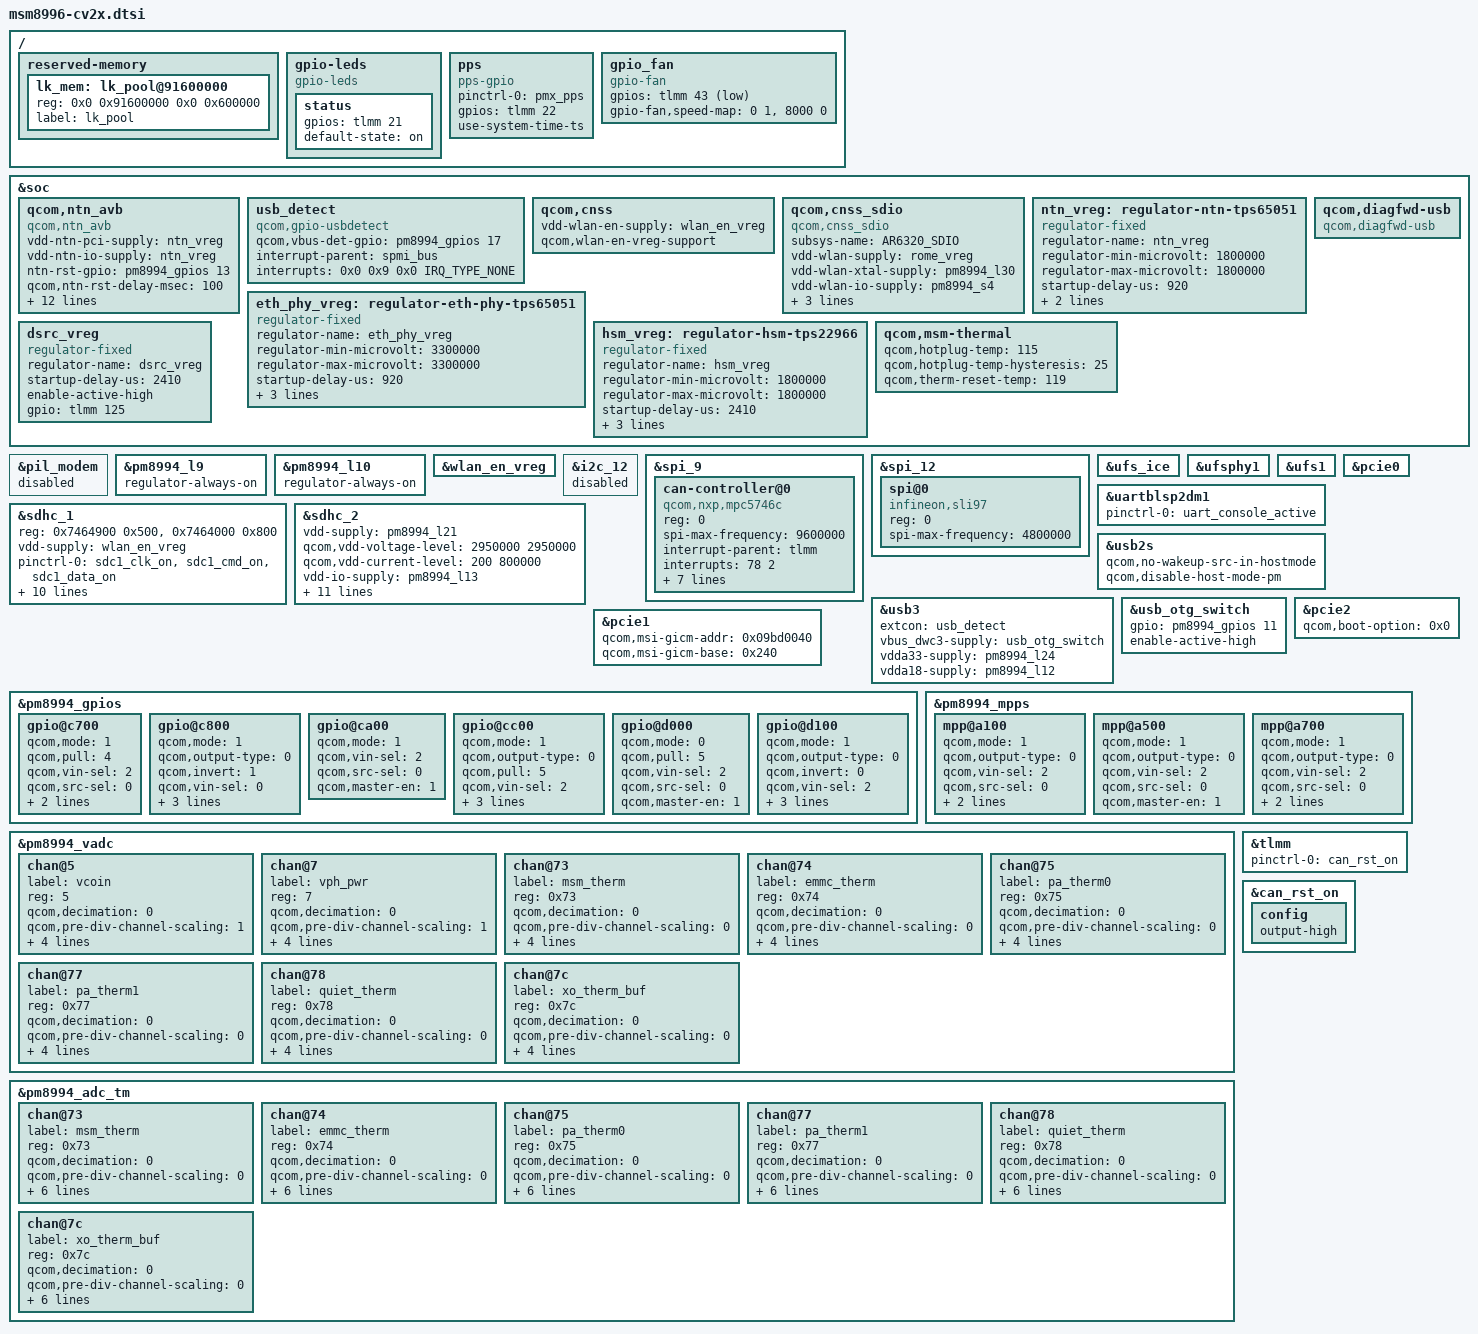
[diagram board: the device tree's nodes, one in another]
/* Copyright (c) 2017-2019, The Linux Foundation. All rights reserved.
 *
 * This program is free software; you can redistribute it and/or modify
 * it under the terms of the GNU General Public License version 2 and
 * only version 2 as published by the Free Software Foundation.
 *
 * This program is distributed in the hope that it will be useful,
 * but WITHOUT ANY WARRANTY; without even the implied warranty of
 * MERCHANTABILITY or FITNESS FOR A PARTICULAR PURPOSE.  See the
 * GNU General Public License for more details.
 */

#include "msm8996-pinctrl.dtsi"
#include "external-soc.dtsi"

/ {
	reserved-memory {
		lk_mem: lk_pool@91600000 {
			reg = <0x0 0x91600000 0x0 0x600000>;
			label = "lk_pool";
		};
	};

	gpio-leds {
		compatible = "gpio-leds";

		status {
			gpios = <&tlmm 21 0>;
			default-state = "on";
		};
	};

	pps {
		compatible = "pps-gpio";
		pinctrl-names = "default";
		pinctrl-0 = <&pmx_pps>;
		gpios = <&tlmm 22 0>;
		status = "okay";
		use-system-time-ts;
	};

	gpio_fan {
		/* Based on 5v 75mA MC30100V2 */
		compatible = "gpio-fan";
		gpios =  <&tlmm 43 GPIO_ACTIVE_LOW>;
		gpio-fan,speed-map = <0     1>,
				     <8000  0>;
	};
};

&soc {
	/delete-node/ sound-9335;

	qcom,ntn_avb {
		compatible = "qcom,ntn_avb";
		vdd-ntn-pci-supply = <&ntn_vreg>;
		vdd-ntn-io-supply = <&ntn_vreg>;
		ntn-rst-gpio = <&pm8994_gpios 13 0>;
		qcom,ntn-rst-delay-msec = <100>;
		qcom,ntn-rc-num = <1>;
		qcom,ntn-bus-num = <1>;
		qcom,ntn-mdio-bus-id = <1>;
		qcom,ntn-phy-addr = <7>;
		qcom,msm-bus,name = "ntn";
		qcom,msm-bus,num-cases = <2>;
		qcom,msm-bus,num-paths = <1>;
		qcom,msm-bus,vectors-KBps =
				<100 512 0 0>,
				<100 512 207108 14432000>;
		qcom,ntn-pcierst-resx;
		qcom,txc-skew-ps = <1860>;
		qcom,rxc-skew-ps = <1860>;
	};

	usb_detect: usb_detect {
		compatible = "qcom,gpio-usbdetect";
		qcom,vbus-det-gpio = <&pm8994_gpios 17 0>;
		interrupt-parent = <&spmi_bus>;
		interrupts = <0x0 0x9 0x0 IRQ_TYPE_NONE>;
		interrupt-names ="pmic_id_irq";
	};

	qcom,cnss {
		vdd-wlan-en-supply = <&wlan_en_vreg>;
		qcom,wlan-en-vreg-support;
		/delete-property/ wlan-en-gpio;
		/delete-property/ wlan-bootstrap-gpio;
		/delete-property/ vdd-wlan-core-supply;
	};

	qcom,cnss_sdio {
		compatible = "qcom,cnss_sdio";
		subsys-name = "AR6320_SDIO";
		vdd-wlan-supply = <&rome_vreg>;
		vdd-wlan-xtal-supply = <&pm8994_l30>;
		vdd-wlan-io-supply = <&pm8994_s4>;
		vdd-wlan-dsrc-supply = <&dsrc_vreg>;
		qcom,wlan-ramdump-dynamic = <0x200000>;
		qcom,skip-wlan-en-toggle;
	};

	ntn_vreg: regulator-ntn-tps65051 {
		compatible = "regulator-fixed";
		regulator-name = "ntn_vreg";
		regulator-min-microvolt = <1800000>;
		regulator-max-microvolt = <1800000>;
		startup-delay-us = <920>;
		gpio = <&tlmm 138 0>;
		enable-active-high;
	};

	eth_phy_vreg: regulator-eth-phy-tps65051 {
		compatible = "regulator-fixed";
		regulator-name = "eth_phy_vreg";
		regulator-min-microvolt = <3300000>;
		regulator-max-microvolt = <3300000>;
		startup-delay-us = <920>;
		gpio = <&tlmm 136 0>;
		enable-active-high;
		regulator-always-on;
	};

	hsm_vreg: regulator-hsm-tps22966 {
		compatible = "regulator-fixed";
		regulator-name = "hsm_vreg";
		regulator-min-microvolt = <1800000>;
		regulator-max-microvolt = <1800000>;
		startup-delay-us = <2410>;
		gpio = <&tlmm 81 0>;
		enable-active-high;
		regulator-always-on;
	};

	dsrc_vreg: dsrc_vreg {
		compatible = "regulator-fixed";
		regulator-name = "dsrc_vreg";
		startup-delay-us = <2410>;
		enable-active-high;
		gpio = <&tlmm 125 0>;
	};

	qcom,diagfwd-usb {
		compatible = "qcom,diagfwd-usb";
		status = "okay";
	};
};

/delete-node/ &mdss_mdp;
/delete-node/ &mdss_dsi;
/delete-node/ &msm_ext_disp;
/delete-node/ &msm_wb_disp;
/delete-node/ &mdss_hdmi_tx;
/delete-node/ &mdss_rotator;
/delete-node/ &routing;

&pil_modem {
	status = "disabled";
};

&pm8994_l9 {
	regulator-always-on;
};

&pm8994_l10 {
	regulator-always-on;
};

&wlan_en_vreg {
	status = "okay";
};

&i2c_12 {
	status = "disabled";
};

&spi_9 {
	status = "okay";

	can-controller@0 {
		compatible = "qcom,nxp,mpc5746c";
		reg = <0>;
		spi-max-frequency = <9600000>;
		interrupt-parent = <&tlmm>;
		interrupts = <78 2>;
		qcom,clk-freq-mhz = <20000000>;
		qcom,max-can-channels = <2>;
		qcom,bits-per-word = <8>;
		qcom,reset-delay-msec = <300>;
		qcom,can-fw-cmd-timeout-req;
		qcom,can-fw-cmd-timeout-ms = <400>;
		qcom,rem-all-buffering-timeout-ms = <2000>;
	};
};

&spi_12 {
	status = "okay";

	/* HSM module */
	spi@0 {
		compatible = "infineon,sli97";
		reg = <0>;
		spi-max-frequency = <4800000>;
	};
};

&ufs_ice {
	status = "okay";
};

&ufsphy1 {
	status = "okay";
};

&ufs1 {
	status = "okay";
};

&uartblsp2dm1 {
	status = "okay";
	pinctrl-names = "default";
	pinctrl-0 = <&uart_console_active>;
};

/* Rome SDIO */
&sdhc_1 {
	reg = <0x7464900 0x500>, <0x7464000 0x800>;
	reg-names = "hc_mem", "core_mem";

	vdd-supply = <&wlan_en_vreg>;

	pinctrl-names = "active", "sleep";
	pinctrl-0 = <&sdc1_clk_on  &sdc1_cmd_on &sdc1_data_on>;
	pinctrl-1 = <&sdc1_clk_off &sdc1_cmd_off &sdc1_data_off>;

	qcom,clk-rates = <400000 20000000 25000000 50000000
				96000000 192000000>;
	qcom,bus-speed-mode = "SDR12", "SDR25", "SDR50", "DDR50", "SDR104";

	qcom,bus-width = <4>;
	qcom,core_3_0v_support;
	qcom,nonremovable;
	qcom,force-sdhc1-probe;

	status = "okay";
};

/* SDCARD slot */
&sdhc_2 {
	vdd-supply = <&pm8994_l21>;
	qcom,vdd-voltage-level = <2950000 2950000>;
	qcom,vdd-current-level = <200 800000>;

	vdd-io-supply = <&pm8994_l13>;
	qcom,vdd-io-voltage-level = <1800000 2950000>;
	qcom,vdd-io-current-level = <200 22000>;

	pinctrl-names = "active", "sleep";
	pinctrl-0 = <&sdc2_clk_on  &sdc2_cmd_on &sdc2_data_on
			&sdc2_cd_on_sbc>;
	pinctrl-1 = <&sdc2_clk_off &sdc2_cmd_off &sdc2_data_off
			&sdc2_cd_off_sbc>;

	qcom,clk-rates = <400000 20000000 25000000
				50000000 100000000 200000000>;
	qcom,bus-speed-mode = "SDR12", "SDR25", "SDR50", "DDR50", "SDR104";

	cd-gpios = <&tlmm 38 GPIO_ACTIVE_LOW>;

	status = "okay";
};

&usb2s {
	status = "okay";
	qcom,no-wakeup-src-in-hostmode;
	qcom,disable-host-mode-pm;
};

&usb3 {
	extcon = <&usb_detect>;
	vbus_dwc3-supply = <&usb_otg_switch>;
	vdda33-supply = <&pm8994_l24>;
	vdda18-supply = <&pm8994_l12>;
};

&usb_otg_switch {
	gpio = <&pm8994_gpios 11 0>;
	enable-active-high;
	status = "ok";
	/delete-property/ vin-supply;
};

&pcie0 {
	/delete-property/ qcom,l1-supported;
	/delete-property/ qcom,l1ss-supported;
};

&pcie1 {
	qcom,msi-gicm-addr = <0x09bd0040>;
	qcom,msi-gicm-base = <0x240>;
	/delete-property/ qcom,l1-supported;
	/delete-property/ qcom,l1ss-supported;
};

&pcie2 {
	/* Enumerate MDM on wake interrupt */
	qcom,boot-option = <0x0>;
	/delete-property/ qcom,l1-supported;
	/delete-property/ qcom,l1ss-supported;
};

&pm8994_gpios {
	gpio@c700 { /* GPIO 8 - WLAN_EN */
		qcom,mode = <1>;		/* Digital output*/
		qcom,pull = <4>;		/* Pulldown 10uA */
		qcom,vin-sel = <2>;		/* VIN2 */
		qcom,src-sel = <0>;		/* GPIO */
		qcom,invert = <0>;		/* Invert */
		qcom,master-en = <1>;		/* Enable GPIO */
		status = "okay";
	};

	gpio@c800 { /* GPIO 9 - Rome 3.3V control */
		qcom,mode = <1>;		/* Digital output */
		qcom,output-type = <0>;		/* MOS logic */
		qcom,invert = <1>;		/* Output high */
		qcom,vin-sel = <0>;		/* VPH_PWR */
		qcom,src-sel = <0>;		/* Constant */
		qcom,out-strength = <1>;	/* High drive strength */
		qcom,master-en = <1>;		/* Enable GPIO */
		status = "okay";
	};

	gpio@ca00 { /* GPIO 11 - USB ENB1 (otg switch) */
		qcom,mode = <1>;		/* DIGITAL OUT */
		qcom,vin-sel = <2>;		/* 1.8 */
		qcom,src-sel = <0>;		/* GPIO */
		qcom,master-en = <1>;		/* Enable GPIO */
		status = "okay";
	};

	gpio@cc00 { /* GPIO 13 - NTN_RST */
		qcom,mode = <1>; /* DIGITAL OUT */
		qcom,output-type = <0>; /* CMOS logic */
		qcom,pull = <5>;
		qcom,vin-sel = <2>; /* 1.8 */
		qcom,out-strength = <1>;
		qcom,src-sel = <0>; /* GPIO */
		qcom,master-en = <1>; /* Enable GPIO */
		status = "okay";
	};

	gpio@d000 { /* GPIO 17 - USB1 VBUS detect */
		qcom,mode = <0>;		/* Digital Input*/
		qcom,pull = <5>;		/* No pull */
		qcom,vin-sel = <2>;		/* 1.8 V */
		qcom,src-sel = <0>;		/* GPIO */
		qcom,master-en = <1>;		/* Enable GPIO */
		status = "okay";
	};

	gpio@d100 { /* GPIO 18 - Rome Sleep Clock */
		qcom,mode = <1>;		/* Digital output */
		qcom,output-type = <0>;		/* CMOS logic */
		qcom,invert = <0>;		/* Output low initially */
		qcom,vin-sel = <2>;		/* VIN 2 */
		qcom,src-sel = <3>;		/* Function 2 */
		qcom,out-strength = <2>;	/* Medium */
		qcom,master-en = <1>;		/* Enable GPIO */
		status = "okay";
	};
};

&pm8994_mpps {
	mpp@a100 { /* MPP 2 */
		/* MDM_RESIN_N control */
		qcom,mode = <1>;		/* Digital output */
		qcom,output-type = <0>;		/* CMOS logic */
		qcom,vin-sel = <2>;		/* S4 1.8V */
		qcom,src-sel = <0>;		/* Constant */
		qcom,master-en = <1>;		/* Enable GPIO */
		qcom,invert = <1>;		/* Output high */
		status = "okay";
	};

	mpp@a500 { /* MPP 6 */
		qcom,mode = <1>;		/* Digital output */
		qcom,output-type = <0>;		/* CMOS logic */
		qcom,vin-sel = <2>;		/* S4 1.8V */
		qcom,src-sel = <0>;		/* Constant */
		qcom,master-en = <1>;		/* Enable GPIO */
		status = "okay";
	};

	mpp@a700 { /* MPP 8 */
		/* MDM_PON_1 control */
		qcom,mode = <1>;		/* Digital output */
		qcom,output-type = <0>;		/* CMOS logic */
		qcom,vin-sel = <2>;		/* S4 1.8V */
		qcom,src-sel = <0>;		/* Constant */
		qcom,master-en = <1>;		/* Enable GPIO */
		qcom,invert = <1>;		/* Output high */
		status = "okay";
	};
};

&pm8994_vadc {
	chan@5 {
		label = "vcoin";
		reg = <5>;
		qcom,decimation = <0>;
		qcom,pre-div-channel-scaling = <1>;
		qcom,calibration-type = "absolute";
		qcom,scale-function = <0>;
		qcom,hw-settle-time = <0>;
		qcom,fast-avg-setup = <0>;
	};

	chan@7 {
		label = "vph_pwr";
		reg = <7>;
		qcom,decimation = <0>;
		qcom,pre-div-channel-scaling = <1>;
		qcom,calibration-type = "absolute";
		qcom,scale-function = <0>;
		qcom,hw-settle-time = <0>;
		qcom,fast-avg-setup = <0>;
	};

	chan@73 {
		label = "msm_therm";
		reg = <0x73>;
		qcom,decimation = <0>;
		qcom,pre-div-channel-scaling = <0>;
		qcom,calibration-type = "ratiometric";
		qcom,scale-function = <2>;
		qcom,hw-settle-time = <2>;
		qcom,fast-avg-setup = <0>;
	};

	chan@74 {
		label = "emmc_therm";
		reg = <0x74>;
		qcom,decimation = <0>;
		qcom,pre-div-channel-scaling = <0>;
		qcom,calibration-type = "ratiometric";
		qcom,scale-function = <2>;
		qcom,hw-settle-time = <2>;
		qcom,fast-avg-setup = <0>;
	};

	chan@75 {
		label = "pa_therm0";
		reg = <0x75>;
		qcom,decimation = <0>;
		qcom,pre-div-channel-scaling = <0>;
		qcom,calibration-type = "ratiometric";
		qcom,scale-function = <2>;
		qcom,hw-settle-time = <2>;
		qcom,fast-avg-setup = <0>;
	};

	chan@77 {
		label = "pa_therm1";
		reg = <0x77>;
		qcom,decimation = <0>;
		qcom,pre-div-channel-scaling = <0>;
		qcom,calibration-type = "ratiometric";
		qcom,scale-function = <2>;
		qcom,hw-settle-time = <2>;
		qcom,fast-avg-setup = <0>;
	};

	chan@78 {
		label = "quiet_therm";
		reg = <0x78>;
		qcom,decimation = <0>;
		qcom,pre-div-channel-scaling = <0>;
		qcom,calibration-type = "ratiometric";
		qcom,scale-function = <2>;
		qcom,hw-settle-time = <2>;
		qcom,fast-avg-setup = <0>;
	};

	chan@7c {
		label = "xo_therm_buf";
		reg = <0x7c>;
		qcom,decimation = <0>;
		qcom,pre-div-channel-scaling = <0>;
		qcom,calibration-type = "ratiometric";
		qcom,scale-function = <4>;
		qcom,hw-settle-time = <2>;
		qcom,fast-avg-setup = <0>;
	};
};

&pm8994_adc_tm {
	chan@73 {
		label = "msm_therm";
		reg = <0x73>;
		qcom,decimation = <0>;
		qcom,pre-div-channel-scaling = <0>;
		qcom,calibration-type = "ratiometric";
		qcom,scale-function = <2>;
		qcom,hw-settle-time = <2>;
		qcom,fast-avg-setup = <0>;
		qcom,btm-channel-number = <0x48>;
		qcom,thermal-node;
	};

	chan@74 {
		label = "emmc_therm";
		reg = <0x74>;
		qcom,decimation = <0>;
		qcom,pre-div-channel-scaling = <0>;
		qcom,calibration-type = "ratiometric";
		qcom,scale-function = <2>;
		qcom,hw-settle-time = <2>;
		qcom,fast-avg-setup = <0>;
		qcom,btm-channel-number = <0x68>;
		qcom,thermal-node;
	};

	chan@75 {
		label = "pa_therm0";
		reg = <0x75>;
		qcom,decimation = <0>;
		qcom,pre-div-channel-scaling = <0>;
		qcom,calibration-type = "ratiometric";
		qcom,scale-function = <2>;
		qcom,hw-settle-time = <2>;
		qcom,fast-avg-setup = <0>;
		qcom,btm-channel-number = <0x70>;
		qcom,thermal-node;
	};

	chan@77 {
		label = "pa_therm1";
		reg = <0x77>;
		qcom,decimation = <0>;
		qcom,pre-div-channel-scaling = <0>;
		qcom,calibration-type = "ratiometric";
		qcom,scale-function = <2>;
		qcom,hw-settle-time = <2>;
		qcom,fast-avg-setup = <0>;
		qcom,btm-channel-number = <0x78>;
		qcom,thermal-node;
	};

	chan@78 {
		label = "quiet_therm";
		reg = <0x78>;
		qcom,decimation = <0>;
		qcom,pre-div-channel-scaling = <0>;
		qcom,calibration-type = "ratiometric";
		qcom,scale-function = <2>;
		qcom,hw-settle-time = <2>;
		qcom,fast-avg-setup = <0>;
		qcom,btm-channel-number = <0x80>;
		qcom,thermal-node;
	};

	chan@7c {
		label = "xo_therm_buf";
		reg = <0x7c>;
		qcom,decimation = <0>;
		qcom,pre-div-channel-scaling = <0>;
		qcom,calibration-type = "ratiometric";
		qcom,scale-function = <4>;
		qcom,hw-settle-time = <2>;
		qcom,fast-avg-setup = <0>;
		qcom,btm-channel-number = <0x88>;
		qcom,thermal-node;
	};
};

&soc {
	qcom,msm-thermal {
		qcom,hotplug-temp = <115>;
		qcom,hotplug-temp-hysteresis = <25>;
		qcom,therm-reset-temp = <119>;
	};
};

&tlmm {
	pinctrl-names = "default";
	pinctrl-0 = <&can_rst_on>;
};

&can_rst_on {
	config {
		output-high;
	};
};
